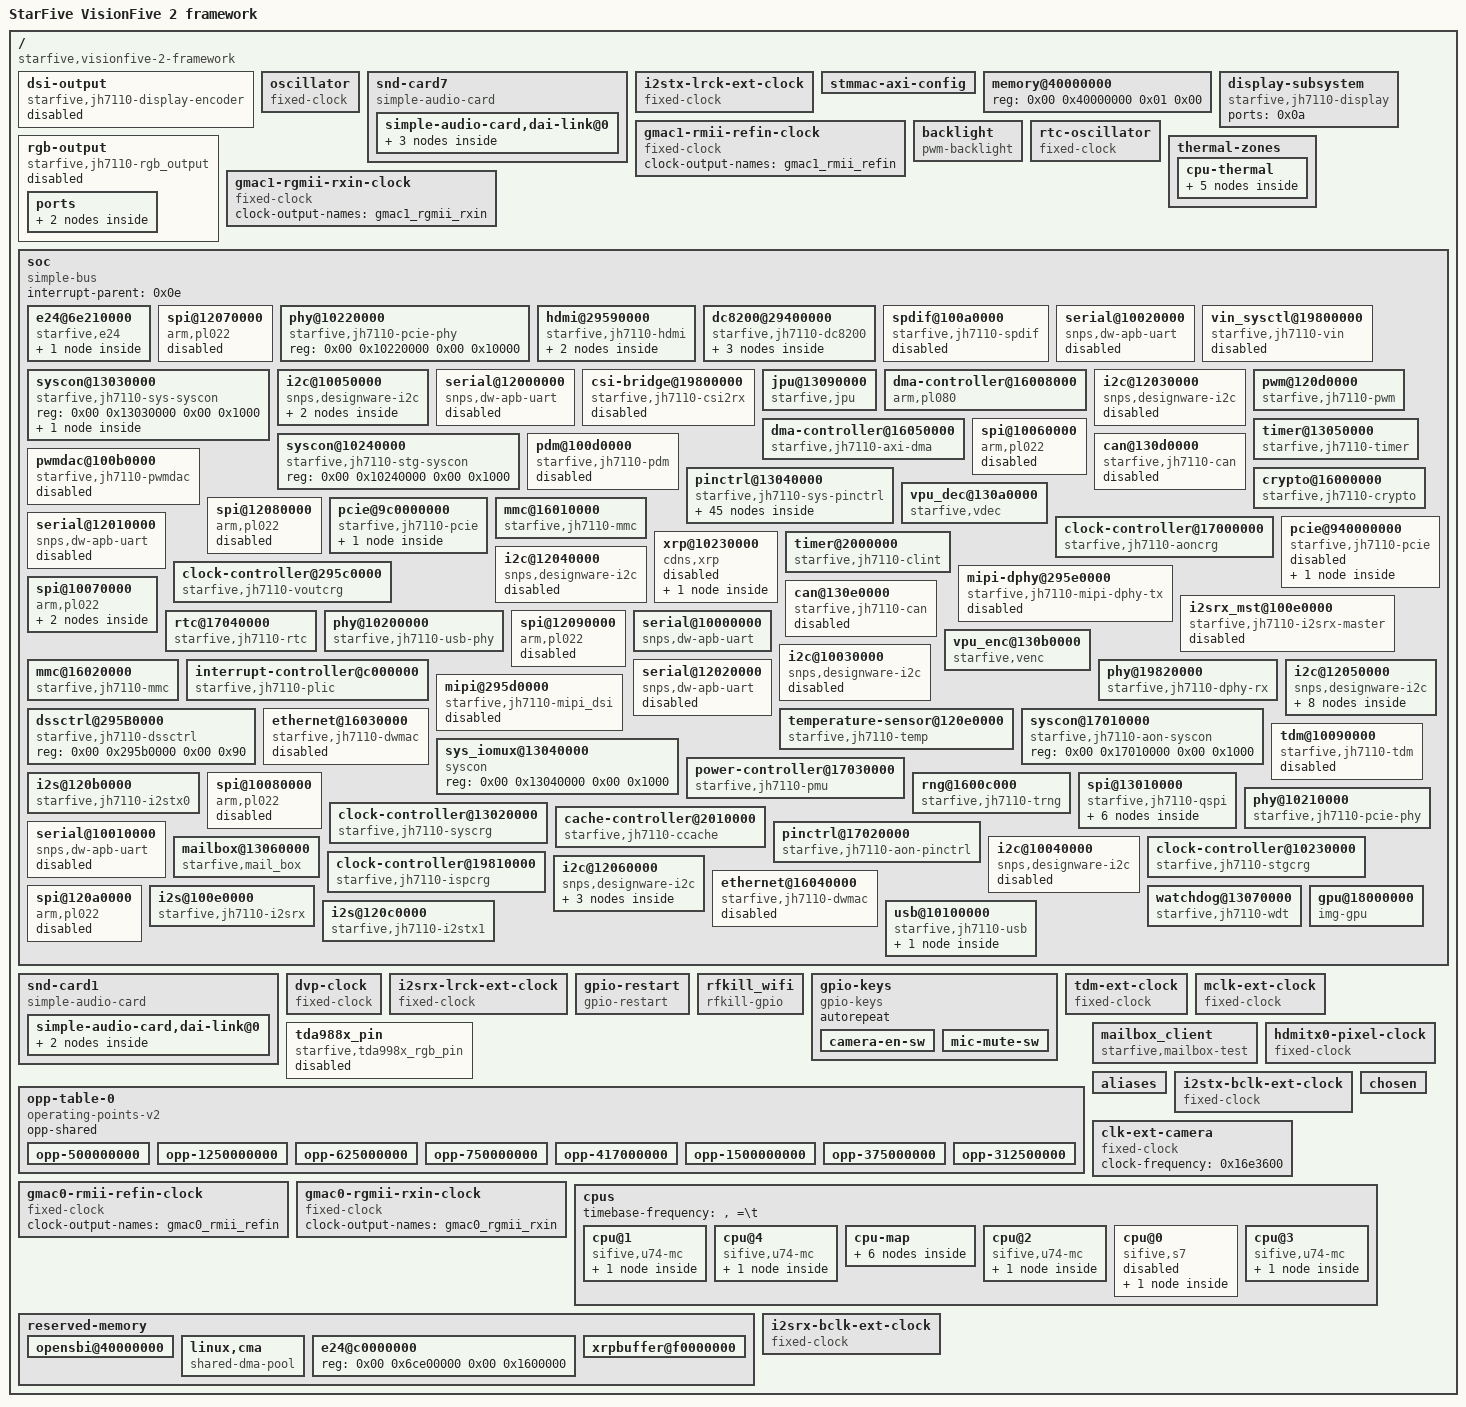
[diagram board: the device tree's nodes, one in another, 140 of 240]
/dts-v1/;

/ {
	#address-cells = <0x02>;
	model = "StarFive VisionFive 2 framework";
	serial-number = "FML13V01-2451-D008EC00-00000902";
	#size-cells = <0x02>;
	compatible = "starfive,visionfive-2-framework", "starfive,jh7110";

	dsi-output {
		compatible = "starfive,jh7110-display-encoder", "verisilicon,dsi-encoder";
		status = "disabled";
	};

	oscillator {
		clock-output-names = "osc";
		#clock-cells = <0x00>;
		clock-frequency = <0x16e3600>;
		compatible = "fixed-clock";
		phandle = <0x25>;
	};

	snd-card7 {
		simple-audio-card,name = "Starfive-ES8326-Sound-Card";
		#address-cells = <0x01>;
		#size-cells = <0x00>;
		compatible = "simple-audio-card";

		simple-audio-card,dai-link@0 {
			mclk-fs = <0x100>;
			format = "i2s";
			frame-master = <0x4f>;
			status = "okay";
			bitclock-master = <0x4f>;
			reg = <0x00>;

			cpu1 {
				sound-dai = <0x51>;
			};

			codec {
				phandle = <0x4f>;
				sound-dai = <0x52>;
			};

			cpu0 {
				sound-dai = <0x50>;
			};
		};
	};

	i2stx-lrck-ext-clock {
		clock-output-names = "i2stx_lrck_ext";
		#clock-cells = <0x00>;
		clock-frequency = <0x2ee00>;
		compatible = "fixed-clock";
		phandle = <0x2a>;
	};

	stmmac-axi-config {
		snps,lpi_en;
		snps,wr_osr_lmt = <0x0f>;
		phandle = <0x37>;
		snps,blen = <0x100 0x80 0x40 0x20 0x00 0x00 0x00>;
		snps,rd_osr_lmt = <0x0f>;
	};

	memory@40000000 {
		device_type = "memory";
		reg = <0x00 0x40000000 0x01 0x00>;
	};

	gmac1-rmii-refin-clock {
		clock-output-names = "gmac1_rmii_refin";
		#clock-cells = <0x00>;
		compatible = "fixed-clock";
		phandle = <0x2d>;
	};

	display-subsystem {
		ports = <0x0a>;
		compatible = "starfive,jh7110-display", "verisilicon,display-subsystem";
		status = "okay";
	};

	backlight {
		default-brightness-level = <0xff>;
		compatible = "pwm-backlight";
		status = "okay";
		brightness-levels = <0x00 0x01 0x02 0x03 0x04 0x05 0x06 0x07 0x08 0x09 0x0a 0x0b 0x0c 0x0d 0x0e 0x0f 0x10 0x11 0x12 0x13 0x14 0x15 0x16 0x17 0x18 0x19 0x1a 0x1b 0x1c 0x1d 0x1e 0x1f 0x20 0x21 0x22 0x23 0x24 0x25 0x26 0x27 0x28 0x29 0x2a 0x2b 0x2c 0x2d 0x2e 0x2f 0x30 0x31 0x32 0x33 0x34 0x35 0x36 0x37 0x38 0x39 0x3a 0x3b 0x3c 0x3d 0x3e 0x3f 0x40 0x41 0x42 0x43 0x44 0x45 0x46 0x47 0x48 0x49 0x4a 0x4b 0x4c 0x4d 0x4e 0x4f 0x50 0x51 0x52 0x53 0x54 0x55 0x56 0x57 0x58 0x59 0x5a 0x5b 0x5c 0x5d 0x5e 0x5f 0x60 0x61 0x62 0x63 0x64 0x65 0x66 0x67 0x68 0x69 0x6a 0x6b 0x6c 0x6d 0x6e 0x6f 0x70 0x71 0x72 0x73 0x74 0x75 0x76 0x77 0x78 0x79 0x7a 0x7b 0x7c 0x7d 0x7e 0x7f 0x80 0x81 0x82 0x83 0x84 0x85 0x86 0x87 0x88 0x89 0x8a 0x8b 0x8c 0x8d 0x8e 0x8f 0x90 0x91 0x92 0x93 0x94 0x95 0x96 0x97 0x98 0x99 0x9a 0x9b 0x9c 0x9d 0x9e 0x9f 0xa0 0xa1 0xa2 0xa3 0xa4 0xa5 0xa6 0xa7 0xa8 0xa9 0xaa 0xab 0xac 0xad 0xae 0xaf 0xb0 0xb1 0xb2 0xb3 0xb4 0xb5 0xb6 0xb7 0xb8 0xb9 0xba 0xbb 0xbc 0xbd 0xbe 0xbf 0xc0 0xc1 0xc2 0xc3 0xc4 0xc5 0xc6 0xc7 0xc8 0xc9 0xca 0xcb 0xcc 0xcd 0xce 0xcf 0xd0 0xd1 0xd2 0xd3 0xd4 0xd5 0xd6 0xd7 0xd8 0xd9 0xda 0xdb 0xdc 0xdd 0xde 0xdf 0xe0 0xe1 0xe2 0xe3 0xe4 0xe5 0xe6 0xe7 0xe8 0xe9 0xea 0xeb 0xec 0xed 0xee 0xef 0xf0 0xf1 0xf2 0xf3 0xf4 0xf5 0xf6 0xf7 0xf8 0xf9 0xfa 0xfb 0xfc 0xfd 0xfe 0xff>;
		pwms = <0x4e 0x00 0x4c4b40 0x00>;
	};

	rgb-output {
		compatible = "starfive,jh7110-rgb_output", "verisilicon,rgb-encoder";
		status = "disabled";

		ports {
			#address-cells = <0x01>;
			#size-cells = <0x00>;

			port@0 {
				#address-cells = <0x01>;
				#size-cells = <0x00>;
				reg = <0x00>;

				endpoint@0 {
					remote-endpoint = <0x0a>;
					reg = <0x00>;
					phandle = <0x42>;
				};
			};
		};
	};

	rtc-oscillator {
		clock-output-names = "rtc_osc";
		#clock-cells = <0x00>;
		clock-frequency = <0x8000>;
		compatible = "fixed-clock";
		phandle = <0x3b>;
	};

	thermal-zones {

		cpu-thermal {
			polling-delay = <0x3a98>;
			polling-delay-passive = <0xfa>;
			thermal-sensors = <0x0c>;

			trips {

				cpu_crit {
					temperature = <0x186a0>;
					hysteresis = <0x7d0>;
					type = "critical";
				};

				cpu_alert0 {
					temperature = <0x14c08>;
					hysteresis = <0x7d0>;
					type = "passive";
					phandle = <0x0d>;
				};
			};

			cooling-maps {

				map0 {
					trip = <0x0d>;
					cooling-device = <0x06 0xffffffff 0xffffffff 0x07 0xffffffff 0xffffffff 0x08 0xffffffff 0xffffffff 0x09 0xffffffff 0xffffffff>;
				};
			};
		};
	};

	gmac1-rgmii-rxin-clock {
		clock-output-names = "gmac1_rgmii_rxin";
		#clock-cells = <0x00>;
		compatible = "fixed-clock";
		phandle = <0x2e>;
	};

	soc {
		#address-cells = <0x02>;
		#size-cells = <0x02>;
		interrupt-parent = <0x0e>;
		compatible = "simple-bus";
		ranges;

		e24@6e210000 {
			#address-cells = <0x01>;
			dma-coherent;
			clock-names = "clk_rtc", "clk_core", "clk_dbg";
			reg-names = "ecmd", "espace";
			irq-mode = <0x01>;
			firmware-name = "e24_elf";
			starfive,stg-syscon = <0x20>;
			resets = <0x22 0x04>;
			memory-region = <0x49>;
			clocks = <0x22 0x18 0x22 0x19 0x22 0x1a>;
			#size-cells = <0x01>;
			interrupt-parent = <0x0e>;
			compatible = "starfive,e24";
			ranges = <0x6ce00000 0x00 0x6ce00000 0x1600000>;
			status = "okay";
			reg = <0x00 0x6e210000 0x00 0x1000 0x00 0x6e211000 0x00 0x3f000>;
			mboxes = <0x0b 0x00 0x02 0x0b 0x02 0x00>;
			reset-names = "e24_core";
			mbox-names = "tx", "rx";

			dsp@0 {
			};
		};

		spi@12070000 {
			arm,primecell-periphid = <0x41022>;
			#address-cells = <0x01>;
			num-cs = <0x01>;
			clock-names = "sspclk", "apb_pclk";
			resets = <0x03 0x48>;
			interrupts = <0x34>;
			clocks = <0x03 0x86 0x03 0x86>;
			#size-cells = <0x00>;
			compatible = "arm,pl022", "arm,primecell";
			status = "disabled";
			reg = <0x00 0x12070000 0x00 0x10000>;
		};

		phy@10220000 {
			#phy-cells = <0x00>;
			compatible = "starfive,jh7110-pcie-phy";
			reg = <0x00 0x10220000 0x00 0x10000>;
			phandle = <0x4c>;
		};

		hdmi@29590000 {
			pinctrl-names = "default";
			hdmi_0p9-supply = <0x45>;
			pinctrl-0 = <0x44>;
			clock-names = "sysclk", "mclk", "bclk", "pclk";
			hdmi_1p8-supply = <0x46>;
			resets = <0x40 0x09>;
			interrupts = <0x63>;
			clocks = <0x40 0x11 0x40 0x0f 0x40 0x10 0x41>;
			hpd-gpio = <0x16 0x0f 0x00>;
			#sound-dai-cells = <0x00>;
			compatible = "starfive,jh7110-hdmi", "inno,hdmi";
			status = "okay";
			reg = <0x00 0x29590000 0x00 0x4000>;
			phandle = <0x55>;
			reset-names = "hdmi_tx";

			port {
				#address-cells = <0x01>;
				#size-cells = <0x00>;

				endpoint@0 {
					remote-endpoint = <0x47>;
					reg = <0x00>;
					phandle = <0x43>;
				};
			};
		};

		dc8200@29400000 {
			verisilicon,dss-syscon = <0x3f>;
			clock-names = "noc_disp", "vout_src", "top_vout_axi", "top_vout_ahb", "pix_clk", "vout_pix1", "axi_clk", "core_clk", "vout_ahb", "vout_top_axi", "vout_top_lcd", "hdmitx0_pixelclk", "dc8200_pix0";
			resets = <0x03 0x2b 0x40 0x00 0x40 0x01 0x40 0x02 0x03 0x1a>;
			interrupts = <0x5f>;
			clocks = <0x03 0x3c 0x03 0x3a 0x03 0x3e 0x03 0x3d 0x40 0x07 0x40 0x08 0x40 0x04 0x40 0x05 0x40 0x06 0x03 0x3e 0x40 0x09 0x41 0x40 0x01>;
			compatible = "starfive,jh7110-dc8200", "verisilicon,dc8200";
			status = "okay";
			reg = <0x00 0x29400000 0x00 0x100 0x00 0x29400800 0x00 0x2000 0x00 0x17030000 0x00 0x1000>;
			reset-names = "rst_vout_src", "rst_axi", "rst_ahb", "rst_core", "rst_noc_disp";

			port {
				#address-cells = <0x01>;
				#size-cells = <0x00>;

				endpoint@1 {
					remote-endpoint = <0x43>;
					reg = <0x01>;
					phandle = <0x47>;
				};

				endpoint@0 {
					remote-endpoint = <0x42>;
					reg = <0x00>;
					phandle = <0x0a>;
				};
			};
		};

		spdif@100a0000 {
			clock-names = "apb", "core", "audroot", "mclk_inner", "mclk_ext", "mclk";
			resets = <0x03 0x5f>;
			interrupts = <0x54>;
			clocks = <0x03 0x9f 0x03 0xa0 0x03 0x10 0x03 0x11 0x1b 0x03 0x12>;
			#sound-dai-cells = <0x00>;
			compatible = "starfive,jh7110-spdif";
			status = "disabled";
			interrupt-names = "tx";
			reg = <0x00 0x100a0000 0x00 0x1000>;
			reset-names = "apb";
		};

		serial@10020000 {
			reg-io-width = <0x04>;
			clock-names = "baudclk", "apb_pclk";
			resets = <0x03 0x57 0x03 0x58>;
			interrupts = <0x22>;
			clocks = <0x03 0x96 0x03 0x95>;
			compatible = "snps,dw-apb-uart";
			status = "disabled";
			reg = <0x00 0x10020000 0x00 0x10000>;
			reg-shift = <0x02>;
		};

		vin_sysctl@19800000 {
			power-domains = <0x30 0x05>;
			clock-names = "clk_apb_func", "clk_pclk", "clk_sys_clk", "clk_wrapper_clk_c", "clk_dvp_inv", "clk_axiwr", "clk_mipi_rx0_pxl", "clk_pixel_clk_if0", "clk_pixel_clk_if1", "clk_pixel_clk_if2", "clk_pixel_clk_if3", "clk_m31dphy_cfgclk_in", "clk_m31dphy_refclk_in", "clk_m31dphy_txclkesc_lan0", "clk_ispcore_2x", "clk_isp_axi";
			reg-names = "csi2rx", "vclk", "vrst", "sctrl", "isp", "trst", "pmu", "syscrg";
			resets = <0x3c 0x00 0x3c 0x01 0x3c 0x04 0x3c 0x09 0x3c 0x0a 0x3c 0x0b 0x3c 0x05 0x3c 0x06 0x3c 0x07 0x3c 0x08 0x3c 0x02 0x3c 0x03 0x03 0x29 0x03 0x2a>;
			interrupts = <0x5c 0x57 0x58 0x59 0x5a>;
			clocks = <0x3c 0x00 0x3c 0x06 0x3c 0x07 0x3c 0x0d 0x3c 0x02 0x3c 0x0c 0x3c 0x01 0x3c 0x08 0x3c 0x09 0x3c 0x0a 0x3c 0x0b 0x3c 0x03 0x3c 0x04 0x3c 0x05 0x03 0x33 0x03 0x34>;
			starfive,aon-syscon = <0x38 0x00>;
			compatible = "starfive,jh7110-vin";
			status = "disabled";
			reg = <0x00 0x19800000 0x00 0x10000 0x00 0x19810000 0x00 0x10000 0x00 0x19820000 0x00 0x10000 0x00 0x19840000 0x00 0x10000 0x00 0x19870000 0x00 0x30000 0x00 0x11840000 0x00 0x10000 0x00 0x17030000 0x00 0x10000 0x00 0x13020000 0x00 0x10000>;
			reset-names = "rst_wrapper_p", "rst_wrapper_c", "rst_pclk", "rst_sys_clk", "rst_axird", "rst_axiwr", "rst_pixel_clk_if0", "rst_pixel_clk_if1", "rst_pixel_clk_if2", "rst_pixel_clk_if3", "rst_m31dphy_hw", "rst_m31dphy_b09_always_on", "rst_isp_top_n", "rst_isp_top_axi";
		};

		syscon@13030000 {
			compatible = "starfive,jh7110-sys-syscon", "syscon", "simple-mfd";
			reg = <0x00 0x13030000 0x00 0x1000>;
			phandle = <0x1c>;

			clock-controller {
				clocks = <0x25>;
				#clock-cells = <0x01>;
				compatible = "starfive,jh7110-pll";
				phandle = <0x2f>;
			};
		};

		i2c@10050000 {
			pinctrl-names = "default";
			#address-cells = <0x01>;
			i2c-sda-hold-time-ns = <0x12c>;
			pinctrl-0 = <0x15>;
			clock-names = "ref";
			i2c-scl-falling-time-ns = <0x1fe>;
			i2c-sda-falling-time-ns = <0x1fe>;
			resets = <0x03 0x4e>;
			interrupts = <0x25>;
			clocks = <0x03 0x8c>;
			#size-cells = <0x00>;
			clock-frequency = <0x186a0>;
			compatible = "snps,designware-i2c";
			status = "okay";
			reg = <0x00 0x10050000 0x00 0x10000>;

			es8326@19 {
				spk-ctl-gpio = <0x16 0x31 0x00>;
				everest,mic2-src = [44];
				everest,jack-pol = [0e];
				irq-gpio = <0x16 0x2e 0x00>;
				#sound-dai-cells = <0x00>;
				everest,interrupt-src = [08];
				compatible = "everest,es8326";
				status = "okay";
				reg = <0x19>;
				phandle = <0x52>;
				everest,mic1-src = [00];
				everest,interrupt-clk = [45];
			};

			touchscreen@14 {
				irq-gpios = <0x16 0x1e 0x00>;
				reset-gpios = <0x16 0x1f 0x00>;
				compatible = "goodix,gt911";
				status = "disabled";
				reg = <0x14>;
			};
		};

		serial@12000000 {
			reg-io-width = <0x04>;
			clock-names = "baudclk", "apb_pclk";
			resets = <0x03 0x59 0x03 0x5a>;
			interrupts = <0x2d>;
			clocks = <0x03 0x98 0x03 0x97>;
			compatible = "snps,dw-apb-uart";
			status = "disabled";
			reg = <0x00 0x12000000 0x00 0x10000>;
			reg-shift = <0x02>;
		};

		csi-bridge@19800000 {
			phy-names = "dphy";
			clock-names = "sys_clk", "p_clk", "pixel_if0_clk", "pixel_if1_clk", "pixel_if2_clk", "pixel_if3_clk";
			resets = <0x3c 0x09 0x3c 0x04 0x3c 0x05 0x3c 0x06 0x3c 0x07 0x3c 0x08>;
			clocks = <0x3c 0x07 0x3c 0x06 0x3c 0x08 0x3c 0x09 0x3c 0x0a 0x3c 0x0b>;
			compatible = "starfive,jh7110-csi2rx";
			status = "disabled";
			phys = <0x3d>;
			reg = <0x00 0x19800000 0x00 0x10000>;
			reset-names = "sys", "reg_bank", "pixel_if0", "pixel_if1", "pixel_if2", "pixel_if3";
		};

		jpu@13090000 {
			power-domains = <0x30 0x03>;
			dma-coherent;
			clock-names = "axi_clk", "core_clk", "apb_clk", "noc_bus", "main_clk", "dec_clk";
			resets = <0x03 0x2c 0x03 0x2d 0x03 0x2e>;
			interrupts = <0x0e>;
			clocks = <0x03 0x42 0x03 0x43 0x03 0x44 0x03 0x4c 0x03 0x4b 0x03 0x4a>;
			compatible = "starfive,jpu";
			status = "okay";
			reg = <0x00 0x13090000 0x00 0x300>;
			reset-names = "rst_axi", "rst_core", "rst_apb";
		};

		dma-controller@16008000 {
			memcpy-bus-width = <0x20>;
			arm,primecell-periphid = <0x41080>;
			lli-bus-interface-ahb1;
			clock-names = "apb_pclk";
			resets = <0x22 0x03>;
			interrupts = <0x1d>;
			clocks = <0x22 0x0f>;
			memcpy-burst-size = <0x100>;
			compatible = "arm,pl080", "arm,primecell";
			mem-bus-interface-ahb1;
			reg = <0x00 0x16008000 0x00 0x4000>;
			phandle = <0x31>;
			#dma-cells = <0x02>;
		};

		i2c@12030000 {
			#address-cells = <0x01>;
			clock-names = "ref";
			resets = <0x03 0x4f>;
			interrupts = <0x30>;
			clocks = <0x03 0x8d>;
			#size-cells = <0x00>;
			compatible = "snps,designware-i2c";
			status = "disabled";
			reg = <0x00 0x12030000 0x00 0x10000>;
		};

		dma-controller@16050000 {
			snps,data-width = <0x03>;
			snps,priority = <0x00 0x01 0x02 0x03>;
			clock-names = "core-clk", "cfgr-clk";
			resets = <0x22 0x05 0x22 0x06>;
			interrupts = <0x49>;
			clocks = <0x22 0x1b 0x22 0x1c>;
			snps,axi-max-burst-len = <0x10>;
			snps,dma-masters = <0x01>;
			compatible = "starfive,jh7110-axi-dma";
			snps,block-size = <0x10000 0x10000 0x10000 0x10000>;
			reg = <0x00 0x16050000 0x00 0x10000>;
			phandle = <0x19>;
			dma-channels = <0x04>;
			#dma-cells = <0x01>;
		};

		pwm@120d0000 {
			pinctrl-names = "default";
			pinctrl-0 = <0x2c>;
			resets = <0x03 0x6c>;
			clocks = <0x03 0x79>;
			#pwm-cells = <0x03>;
			compatible = "starfive,jh7110-pwm", "opencores,pwm-v1";
			status = "okay";
			reg = <0x00 0x120d0000 0x00 0x10000>;
			phandle = <0x4e>;
		};

		syscon@10240000 {
			compatible = "starfive,jh7110-stg-syscon", "syscon";
			reg = <0x00 0x10240000 0x00 0x1000>;
			phandle = <0x20>;
		};

		timer@13050000 {
			clock-names = "apb", "ch0", "ch1", "ch2", "ch3";
			resets = <0x03 0x75 0x03 0x76 0x03 0x77 0x03 0x78 0x03 0x79>;
			interrupts = <0x45 0x46 0x47 0x48>;
			clocks = <0x03 0x7c 0x03 0x7d 0x03 0x7e 0x03 0x7f 0x03 0x80>;
			compatible = "starfive,jh7110-timer";
			reg = <0x00 0x13050000 0x00 0x10000>;
			reset-names = "apb", "ch0", "ch1", "ch2", "ch3";
		};

		spi@10060000 {
			arm,primecell-periphid = <0x41022>;
			#address-cells = <0x01>;
			num-cs = <0x01>;
			clock-names = "sspclk", "apb_pclk";
			resets = <0x03 0x45>;
			interrupts = <0x26>;
			clocks = <0x03 0x83 0x03 0x83>;
			#size-cells = <0x00>;
			compatible = "arm,pl022", "arm,primecell";
			status = "disabled";
			reg = <0x00 0x10060000 0x00 0x10000>;
		};

		pdm@100d0000 {
			clock-names = "pdm_mclk", "pdm_apb", "clk_mclk", "mclk_ext";
			reg-names = "pdm";
			resets = <0x03 0x61 0x03 0x62>;
			clocks = <0x03 0xb6 0x03 0xb7 0x03 0x12 0x1b>;
			#sound-dai-cells = <0x00>;
			compatible = "starfive,jh7110-pdm";
			status = "disabled";
			reg = <0x00 0x100d0000 0x00 0x1000>;
			reset-names = "pdm_dmic", "pdm_apb";
		};

		pwmdac@100b0000 {
			clock-names = "apb", "core";
			resets = <0x03 0x60>;
			clocks = <0x03 0x9d 0x03 0x9e>;
			dma-names = "tx";
			#sound-dai-cells = <0x00>;
			compatible = "starfive,jh7110-pwmdac";
			status = "disabled";
			reg = <0x00 0x100b0000 0x00 0x1000>;
			dmas = <0x19 0x16>;
		};

		can@130d0000 {
			syscon,can_or_canfd = <0x00>;
			clock-names = "apb_clk", "core_clk", "timer_clk";
			starfive,sys-syscon = <0x1c 0x10 0x03 0x08>;
			resets = <0x03 0x6f 0x03 0x70 0x03 0x71>;
			interrupts = <0x70>;
			clocks = <0x03 0x73 0x03 0x75 0x03 0x74>;
			compatible = "starfive,jh7110-can", "ipms,can";
			status = "disabled";
			frequency = <0x2625a00>;
			reg = <0x00 0x130d0000 0x00 0x1000>;
			reset-names = "rst_apb", "rst_core", "rst_timer";
		};

		pinctrl@13040000 {
			gpio-controller;
			resets = <0x03 0x02>;
			interrupts = <0x56>;
			clocks = <0x03 0x70>;
			compatible = "starfive,jh7110-sys-pinctrl";
			#interrupt-cells = <0x02>;
			reg = <0x00 0x13040000 0x00 0x10000>;
			phandle = <0x16>;
			#gpio-cells = <0x02>;
			interrupt-controller;

			mmc1-0 {
				phandle = <0x35>;

				clk-pins {
					input-schmitt-disable;
					input-disable;
					drive-strength = <0x0c>;
					pinmux = <0xff37000a>;
					slew-rate = <0x00>;
					bias-pull-up;
				};

				mmc-pins {
					drive-strength = <0x0c>;
					pinmux = <0x2c394c09 0x2d3a500b 0x2e3b540c 0x2f3c5807 0x303d5c08>;
					input-schmitt-enable;
					slew-rate = <0x00>;
					bias-pull-up;
					input-enable;
				};
			};

			i2c2-0 {
				phandle = <0x15>;

				i2c-pins {
					bias-disable;
					pinmux = <0x3b007803 0x3c007c02>;
					input-schmitt-enable;
					input-enable;
				};
			};

			i2c5-0 {
				phandle = <0x26>;

				i2c-pins {
					bias-disable;
					pinmux = <0x4f00a813 0x5000ac14>;
					input-schmitt-enable;
					input-enable;
				};
			};

			mmc0-0 {
				phandle = <0x32>;

				mmc-pins {
					drive-strength = <0x0c>;
					pinmux = <0x440 0x441 0x442 0x443 0x444 0x445 0x446 0x447 0x448 0x449>;
					bias-pull-up;
					input-enable;
				};

				rst-pins {
					input-schmitt-disable;
					input-disable;
					drive-strength = <0x0c>;
					pinmux = <0xff13003e>;
					slew-rate = <0x00>;
					bias-pull-up;
				};
			};

			i2srx-0 {
				phandle = <0x1f>;

				clk-sd-pins {
					pinmux = <0x1f000426 0x2000043f 0x21000426 0x2200043f 0x1700042c>;
					input-enable;
				};
			};

			hdmi-0 {
				phandle = <0x44>;

				cec-pins {
					pinmux = <0x50a080e>;
					bias-pull-up;
					input-enable;
				};

				hpd-pins {
					bias-disable;
					pinmux = <0x800040f>;
					input-enable;
				};

				scl-pins {
					pinmux = <0x60b0c00>;
					bias-pull-up;
					input-enable;
				};

				sda-pins {
					pinmux = <0x70c1001>;
					bias-pull-up;
					input-enable;
				};
			};

			pwmdac-0 {

				pwmdac-pins {
					input-schmitt-disable;
					input-disable;
					drive-strength = <0x02>;
					bias-disable;
					pinmux = <0xff1c0021 0xff1d0022>;
					slew-rate = <0x00>;
				};
			};

			uart0-0 {
				phandle = <0x14>;

				tx-pins {
					input-schmitt-disable;
					input-disable;
					drive-strength = <0x0c>;
					bias-disable;
					pinmux = <0xff140005>;
					slew-rate = <0x00>;
				};

				rx-pins {
					drive-strength = <0x02>;
					bias-disable;
					pinmux = <0xe000406>;
					input-schmitt-enable;
					slew-rate = <0x00>;
					input-enable;
				};
			};

			pcie1-0 {
				phandle = <0x4d>;

				clkreq-pins {
					input-schmitt-disable;
					drive-strength = <0x02>;
					pinmux = <0xff00041d>;
					bias-pull-down;
					slew-rate = <0x00>;
					input-enable;
				};

				wake-pins {
					input-schmitt-disable;
					drive-strength = <0x02>;
					pinmux = <0xff01041c>;
					slew-rate = <0x00>;
					bias-pull-up;
					input-enable;
				};
			};

			tdm-0 {
				phandle = <0x1a>;

				pcmclk-pins {
					pinmux = <0x23010426>;
					input-enable;
				};

				sync-pins {
					pinmux = <0x2501043f>;
					input-enable;
				};

				tx-pins {
					input-schmitt-disable;
					input-disable;
					drive-strength = <0x02>;
					pinmux = <0xff29002c>;
					slew-rate = <0x00>;
					bias-pull-up;
				};

				rx-pins {
					pinmux = <0x2401043d>;
					input-enable;
				};
			};

			i2stx1-0 {
				phandle = <0x2b>;

				sd-pins {
					input-disable;
					bias-disable;
					pinmux = <0xff45003d>;
				};
			};

			i2c6-0 {
				phandle = <0x27>;

				i2c-pins {
					bias-disable;
					pinmux = <0x5600b810 0x5700bc11>;
					input-schmitt-enable;
					input-enable;
				};
			};

			pwm-0 {
				phandle = <0x2c>;

				pwm-pins {
					input-schmitt-disable;
					input-disable;
					drive-strength = <0x0c>;
					bias-disable;
					pinmux = <0xff182416>;
					slew-rate = <0x00>;
				};
			};

			pcie0-0 {

				clkreq-pins {
					input-schmitt-disable;
					drive-strength = <0x02>;
					pinmux = <0xff00041b>;
					bias-pull-down;
					slew-rate = <0x00>;
					input-enable;
				};

				wake-pins {
					input-schmitt-disable;
					drive-strength = <0x02>;
					pinmux = <0xff000420>;
					slew-rate = <0x00>;
					bias-pull-up;
					input-enable;
				};
			};

			mclk-ext-0 {
				phandle = <0x28>;

				mclk-ext-pins {
					pinmux = <0x1e000404>;
					input-enable;
				};
			};

			spi1-0 {
				phandle = <0x17>;

				miso-pins {
					pinmux = <0x3a000424>;
					input-schmitt-enable;
					bias-pull-up;
					input-enable;
				};

				mosi-pins {
					input-schmitt-disable;
					input-disable;
					bias-disable;
					pinmux = <0xff4b0027>;
				};

				sck-pins {
					input-schmitt-disable;
					input-disable;
					bias-disable;
					pinmux = <0x3849003a>;
				};
			};
		};

		crypto@16000000 {
			clock-names = "hclk", "ahb";
			resets = <0x22 0x03>;
			interrupts = <0x1c>;
			clocks = <0x22 0x0f 0x22 0x10>;
			dma-names = "tx", "rx";
			compatible = "starfive,jh7110-crypto";
			reg = <0x00 0x16000000 0x00 0x4000>;
			dmas = <0x31 0x01 0x02 0x31 0x00 0x02>;
		};

		vpu_dec@130a0000 {
			power-domains = <0x30 0x03>;
			dma-coherent;
			clock-names = "axi_clk", "bpu_clk", "vce_clk", "apb_clk", "noc_bus", "main_clk";
			resets = <0x03 0x2f 0x03 0x30 0x03 0x31 0x03 0x32 0x03 0x35>;
			interrupts = <0x0d>;
			clocks = <0x03 0x46 0x03 0x47 0x03 0x48 0x03 0x49 0x03 0x4c 0x03 0x4b>;
			compatible = "starfive,vdec";
			status = "okay";
			reg = <0x00 0x130a0000 0x00 0x10000>;
			starfive,vdec_noc_ctrl;
			reset-names = "rst_axi", "rst_bpu", "rst_vce", "rst_apb", "rst_sram";
		};

		spi@12080000 {
			arm,primecell-periphid = <0x41022>;
			#address-cells = <0x01>;
			num-cs = <0x01>;
			clock-names = "sspclk", "apb_pclk";
			resets = <0x03 0x49>;
			interrupts = <0x35>;
			clocks = <0x03 0x87 0x03 0x87>;
			#size-cells = <0x00>;
			compatible = "arm,pl022", "arm,primecell";
			status = "disabled";
			reg = <0x00 0x12080000 0x00 0x10000>;
		};

		pcie@9c0000000 {
			pinctrl-names = "default";
			#address-cells = <0x03>;
			bus-range = <0x00 0xff>;
			pinctrl-0 = <0x4d>;
			clock-names = "noc", "tl", "axi_mst0", "apb";
			reg-names = "cfg", "apb";
			starfive,stg-syscon = <0x20>;
			resets = <0x22 0x11 0x22 0x12 0x22 0x13 0x22 0x14 0x22 0x15 0x22 0x16>;
			interrupts = <0x39>;
			clocks = <0x03 0x60 0x22 0x0d 0x22 0x0b 0x22 0x0c>;
			interrupt-map = <0x00 0x00 0x00 0x01 0x4b 0x01 0x00 0x00 0x00 0x02 0x4b 0x02 0x00 0x00 0x00 0x03 0x4b 0x03 0x00 0x00 0x00 0x04 0x4b 0x04>;
			#size-cells = <0x02>;
			perst-gpios = <0x16 0x15 0x01>;
			msi-controller;
			device_type = "pci";
			interrupt-map-mask = <0x00 0x00 0x00 0x07>;
			compatible = "starfive,jh7110-pcie";
			ranges = <0x82000000 0x00 0x38000000 0x00 0x38000000 0x00 0x8000000 0xc3000000 0x09 0x80000000 0x09 0x80000000 0x00 0x40000000>;
			#interrupt-cells = <0x01>;
			status = "okay";
			phys = <0x4c>;
			reg = <0x09 0xc0000000 0x00 0x1000000 0x00 0x2c000000 0x00 0x100000>;
			linux,pci-domain = <0x01>;
			reset-names = "mst0", "slv0", "slv", "brg", "core", "apb";

			interrupt-controller {
				#address-cells = <0x00>;
				#interrupt-cells = <0x01>;
				phandle = <0x4b>;
				interrupt-controller;
			};
		};

		mmc@16010000 {
			fifo-depth = <0x20>;
			pinctrl-names = "default";
			data-addr = <0x00>;
			pinctrl-0 = <0x32>;
			clock-names = "biu", "ciu";
			vqmmc-supply = <0x34>;
			assigned-clocks = <0x03 0x5d>;
			mmc-hs200-1_8v;
			bus-width = <0x08>;
			non-removable;
			assigned-clock-rates = <0x2faf080>;
			resets = <0x03 0x40>;
			interrupts = <0x4a>;
			clocks = <0x03 0x5b 0x03 0x5d>;
			vmmc-supply = <0x33>;
			cap-mmc-hw-reset;
			mmc-ddr-1_8v;
			compatible = "starfive,jh7110-mmc";
			post-power-on-delay-ms = <0xc8>;
			status = "okay";
			fifo-watermark-aligned;
			reg = <0x00 0x16010000 0x00 0x10000>;
			max-frequency = <0x5f5e100>;
			cap-mmc-highspeed;
			reset-names = "reset";
			starfive,sysreg = <0x1c 0x14 0x1a 0x7c000000>;
		};

		clock-controller@17000000 {
			#reset-cells = <0x01>;
			clock-names = "osc", "gmac0_rmii_refin", "gmac0_rgmii_rxin", "stg_axiahb", "apb_bus", "gmac0_gtxclk", "rtc_osc";
			clocks = <0x25 0x39 0x3a 0x03 0x08 0x03 0x0b 0x03 0x6c 0x3b>;
			#clock-cells = <0x01>;
			compatible = "starfive,jh7110-aoncrg";
			reg = <0x00 0x17000000 0x00 0x10000>;
			phandle = <0x36>;
		};

		serial@12010000 {
			reg-io-width = <0x04>;
			clock-names = "baudclk", "apb_pclk";
			resets = <0x03 0x5b 0x03 0x5c>;
			interrupts = <0x2e>;
			clocks = <0x03 0x9a 0x03 0x99>;
			compatible = "snps,dw-apb-uart";
			status = "disabled";
			reg = <0x00 0x12010000 0x00 0x10000>;
			reg-shift = <0x02>;
		};

		pcie@940000000 {
			#address-cells = <0x03>;
			bus-range = <0x00 0xff>;
			clock-names = "noc", "tl", "axi_mst0", "apb";
			reg-names = "cfg", "apb";
			starfive,stg-syscon = <0x20>;
			resets = <0x22 0x0b 0x22 0x0c 0x22 0x0d 0x22 0x0e 0x22 0x0f 0x22 0x10>;
			interrupts = <0x38>;
			clocks = <0x03 0x60 0x22 0x0a 0x22 0x08 0x22 0x09>;
			interrupt-map = <0x00 0x00 0x00 0x01 0x4a 0x01 0x00 0x00 0x00 0x02 0x4a 0x02 0x00 0x00 0x00 0x03 0x4a 0x03 0x00 0x00 0x00 0x04 0x4a 0x04>;
			#size-cells = <0x02>;
			msi-controller;
			device_type = "pci";
			interrupt-map-mask = <0x00 0x00 0x00 0x07>;
			compatible = "starfive,jh7110-pcie";
			ranges = <0x82000000 0x00 0x30000000 0x00 0x30000000 0x00 0x8000000 0xc3000000 0x09 0x00 0x09 0x00 0x00 0x40000000>;
			#interrupt-cells = <0x01>;
			status = "disabled";
			phys = <0x24>;
			reg = <0x09 0x40000000 0x00 0x1000000 0x00 0x2b000000 0x00 0x100000>;
			linux,pci-domain = <0x00>;
			reset-names = "mst0", "slv0", "slv", "brg", "core", "apb";

			interrupt-controller {
				#address-cells = <0x00>;
				#interrupt-cells = <0x01>;
				phandle = <0x4a>;
				interrupt-controller;
			};
		};

		xrp@10230000 {
			#address-cells = <0x01>;
			dma-coherent;
			clock-names = "core_clk";
			firmware-name = "hifi4_elf";
			starfive,stg-syscon = <0x20>;
			resets = <0x22 0x01 0x22 0x02>;
			clocks = <0x22 0x00>;
			#size-cells = <0x01>;
			compatible = "cdns,xrp";
			ranges = <0x40000000 0x00 0x20000000 0x40000 0x69c00000 0x00 0x69c00000 0x3000000>;
			status = "disabled";
			reg = <0x00 0x10230000 0x00 0x10000 0x00 0x10240000 0x00 0x10000>;
			reset-names = "rst_core", "rst_axi";

			dsp@0 {
			};
		};

		timer@2000000 {
			interrupts-extended = <0x0f 0x03 0x0f 0x07 0x10 0x03 0x10 0x07 0x11 0x03 0x11 0x07 0x12 0x03 0x12 0x07 0x13 0x03 0x13 0x07>;
			compatible = "starfive,jh7110-clint", "sifive,clint0";
			reg = <0x00 0x2000000 0x00 0x10000>;
		};

		i2c@12040000 {
			#address-cells = <0x01>;
			clock-names = "ref";
			resets = <0x03 0x50>;
			interrupts = <0x31>;
			clocks = <0x03 0x8e>;
			#size-cells = <0x00>;
			compatible = "snps,designware-i2c";
			status = "disabled";
			reg = <0x00 0x12040000 0x00 0x10000>;
		};

		clock-controller@295c0000 {
			power-domains = <0x30 0x04>;
			#reset-cells = <0x01>;
			clock-names = "vout_src", "vout_top_ahb", "vout_top_axi", "vout_top_hdmitx0_mclk", "i2stx0_bclk", "hdmitx0_pixelclk";
			resets = <0x03 0x2b>;
			clocks = <0x03 0x3a 0x03 0x3d 0x03 0x3e 0x03 0x3f 0x03 0xa5 0x41>;
			#clock-cells = <0x01>;
			compatible = "starfive,jh7110-voutcrg";
			reg = <0x00 0x295c0000 0x00 0x10000>;
			phandle = <0x40>;
		};

		mipi-dphy@295e0000 {
			clock-names = "dphy_txesc";
			resets = <0x40 0x0a 0x40 0x0b>;
			clocks = <0x40 0x0e>;
			#phy-cells = <0x00>;
			compatible = "starfive,jh7110-mipi-dphy-tx", "m31,mipi-dphy-tx";
			status = "disabled";
			reg = <0x00 0x295e0000 0x00 0x10000>;
			phandle = <0x48>;
			reset-names = "dphy_sys", "dphy_txbytehs";
		};

		spi@10070000 {
			arm,primecell-periphid = <0x41022>;
			pinctrl-names = "default";
			#address-cells = <0x01>;
			num-cs = <0x01>;
			pinctrl-0 = <0x17>;
			clock-names = "sspclk", "apb_pclk";
			resets = <0x03 0x46>;
			interrupts = <0x27>;
			clocks = <0x03 0x84 0x03 0x84>;
			#size-cells = <0x00>;
			compatible = "arm,pl022", "arm,primecell";
			status = "okay";
			reg = <0x00 0x10070000 0x00 0x10000>;
			cs-gpios = <0x16 0x39 0x01>;

			spi@1 {
				pl022,interface = <0x00>;
				irq-gpio = <0x16 0x1a 0x00>;
				google,cros-ec-spi-msg-delay = <0x0a>;
				spi-max-frequency = <0xf4240>;
				pl022,com-mode = <0x01>;
				compatible = "google,cros-ec-spi";
				status = "okay";
				reg = <0x00>;
				google,cros-ec-spi-pre-delay = <0x0a>;

				keyboard-controller {
					compatible = "google,cros-ec-keyb-switches";
					status = "okay";
				};
			};
		};

		i2srx_mst@100e0000 {
			clock-names = "i2sclk", "apb", "mclk", "mclk_inner", "mclk_ext";
			resets = <0x03 0x63 0x03 0x64>;
			clocks = <0x03 0xb0 0x03 0xaf 0x03 0x12 0x03 0x11 0x1b>;
			dma-names = "rx";
			#sound-dai-cells = <0x00>;
			starfive,syscon = <0x1c 0x18 0x02 0x34 0x3fc00 0x24400>;
			compatible = "starfive,jh7110-i2srx-master";
			status = "disabled";
			reg = <0x00 0x100e0000 0x00 0x1000>;
			dmas = <0x19 0x18>;
		};

		can@130e0000 {
			syscon,can_or_canfd = <0x00>;
			clock-names = "apb_clk", "core_clk", "timer_clk";
			starfive,sys-syscon = <0x1c 0x88 0x12 0x40000>;
			resets = <0x03 0x72 0x03 0x73 0x03 0x74>;
			interrupts = <0x71>;
			clocks = <0x03 0x76 0x03 0x78 0x03 0x77>;
			compatible = "starfive,jh7110-can", "ipms,can";
			status = "disabled";
			frequency = <0x2625a00>;
			reg = <0x00 0x130e0000 0x00 0x1000>;
			reset-names = "rst_apb", "rst_core", "rst_timer";
		};

		rtc@17040000 {
			clock-names = "pclk", "cal_clk";
			resets = <0x36 0x07 0x36 0x05 0x36 0x06>;
			interrupts = <0x0a 0x0b 0x0c>;
			clocks = <0x36 0x0a 0x36 0x0d>;
			compatible = "starfive,jh7110-rtc";
			interrupt-names = "rtc_ms_pulse", "rtc_sec_pulse", "rtc";
			reg = <0x00 0x17040000 0x00 0x10000>;
			reset-names = "rst_osc", "rst_apb", "rst_cal";
			rtc,cal-clock-freq = <0xf4240>;
		};

		phy@10200000 {
			clock-names = "125m", "app_125m";
			clocks = <0x03 0x5f 0x22 0x06>;
			#phy-cells = <0x00>;
			compatible = "starfive,jh7110-usb-phy";
			reg = <0x00 0x10200000 0x00 0x10000>;
			phandle = <0x23>;
		};

		spi@12090000 {
			arm,primecell-periphid = <0x41022>;
			#address-cells = <0x01>;
			num-cs = <0x01>;
			clock-names = "sspclk", "apb_pclk";
			resets = <0x03 0x4a>;
			interrupts = <0x36>;
			clocks = <0x03 0x88 0x03 0x88>;
			#size-cells = <0x00>;
			compatible = "arm,pl022", "arm,primecell";
			status = "disabled";
			reg = <0x00 0x12090000 0x00 0x10000>;
		};

		serial@10000000 {
			reg-io-width = <0x04>;
			pinctrl-names = "default";
			pinctrl-0 = <0x14>;
			clock-names = "baudclk", "apb_pclk";
			resets = <0x03 0x53 0x03 0x54>;
			interrupts = <0x20>;
			clocks = <0x03 0x92 0x03 0x91>;
			compatible = "snps,dw-apb-uart";
			status = "okay";
			reg = <0x00 0x10000000 0x00 0x10000>;
			reg-shift = <0x02>;
		};

		vpu_enc@130b0000 {
			power-domains = <0x30 0x06>;
			dma-coherent;
			clock-names = "axi_clk", "bpu_clk", "vce_clk", "apb_clk", "noc_bus";
			resets = <0x03 0x36 0x03 0x37 0x03 0x38 0x03 0x39 0x03 0x3a>;
			interrupts = <0x0f>;
			clocks = <0x03 0x4e 0x03 0x4f 0x03 0x50 0x03 0x51 0x03 0x52>;
			compatible = "starfive,venc";
			status = "okay";
			reg = <0x00 0x130b0000 0x00 0x10000>;
			starfive,venc_noc_ctrl;
			reset-names = "rst_axi", "rst_bpu", "rst_vce", "rst_apb", "rst_sram";
		};

		i2c@10030000 {
			#address-cells = <0x01>;
			clock-names = "ref";
			resets = <0x03 0x4c>;
			interrupts = <0x23>;
			clocks = <0x03 0x8a>;
			#size-cells = <0x00>;
			compatible = "snps,designware-i2c";
			status = "disabled";
			reg = <0x00 0x10030000 0x00 0x10000>;
		};

		mmc@16020000 {
			fifo-depth = <0x20>;
			pinctrl-names = "default";
			data-addr = <0x00>;
			pinctrl-0 = <0x35>;
			clock-names = "biu", "ciu";
			cap-sd-highspeed;
			assigned-clocks = <0x03 0x5e>;
			no-mmc;
			bus-width = <0x04>;
			no-sdio;
			assigned-clock-rates = <0x2faf080>;
			resets = <0x03 0x41>;
			interrupts = <0x4b>;
			clocks = <0x03 0x5c 0x03 0x5e>;
			broken-cd;
			compatible = "starfive,jh7110-mmc";
			post-power-on-delay-ms = <0xc8>;
			status = "okay";
			fifo-watermark-aligned;
			reg = <0x00 0x16020000 0x00 0x10000>;
			max-frequency = <0x5f5e100>;
			reset-names = "reset";
			starfive,sysreg = <0x1c 0x9c 0x01 0x3e>;
		};

		interrupt-controller@c000000 {
			#address-cells = <0x00>;
			interrupts-extended = <0x0f 0x0b 0x10 0x0b 0x10 0x09 0x11 0x0b 0x11 0x09 0x12 0x0b 0x12 0x09 0x13 0x0b 0x13 0x09>;
			compatible = "starfive,jh7110-plic", "sifive,plic-1.0.0";
			#interrupt-cells = <0x01>;
			reg = <0x00 0xc000000 0x00 0x4000000>;
			phandle = <0x0e>;
			riscv,ndev = <0x88>;
			interrupt-controller;
		};

		phy@19820000 {
			power-domains = <0x38 0x01>;
			clock-names = "cfg", "ref", "tx";
			resets = <0x3c 0x02 0x3c 0x03>;
			clocks = <0x3c 0x03 0x3c 0x04 0x3c 0x05>;
			#phy-cells = <0x00>;
			compatible = "starfive,jh7110-dphy-rx";
			reg = <0x00 0x19820000 0x00 0x10000>;
			phandle = <0x3d>;
		};

		serial@12020000 {
			reg-io-width = <0x04>;
			clock-names = "baudclk", "apb_pclk";
			resets = <0x03 0x5d 0x03 0x5e>;
			interrupts = <0x2f>;
			clocks = <0x03 0x9c 0x03 0x9b>;
			compatible = "snps,dw-apb-uart";
			status = "disabled";
			reg = <0x00 0x12020000 0x00 0x10000>;
			reg-shift = <0x02>;
		};

		dssctrl@295B0000 {
			compatible = "starfive,jh7110-dssctrl", "verisilicon,dss-ctrl", "syscon";
			reg = <0x00 0x295b0000 0x00 0x90>;
			phandle = <0x3f>;
		};

		mipi@295d0000 {
			phy-names = "dphy";
			clock-names = "dpi", "apb", "txesc", "sys";
			reg-names = "dsi";
			resets = <0x40 0x03 0x40 0x04 0x40 0x05 0x40 0x06 0x40 0x07 0x40 0x08>;
			interrupts = <0x62>;
			clocks = <0x40 0x0b 0x40 0x0a 0x40 0x0d 0x40 0x0c>;
			compatible = "starfive,jh7110-mipi_dsi", "cdns,dsi";
			status = "disabled";
			phys = <0x48>;
			reg = <0x00 0x295d0000 0x00 0x10000>;
			reset-names = "dsi_dpi", "dsi_apb", "dsi_rxesc", "dsi_sys", "dsi_txbytehs", "dsi_txesc";
		};

		temperature-sensor@120e0000 {
			clock-names = "sense", "bus";
			resets = <0x03 0x7c 0x03 0x7b>;
			clocks = <0x03 0x82 0x03 0x81>;
			#thermal-sensor-cells = <0x00>;
			compatible = "starfive,jh7110-temp";
			reg = <0x00 0x120e0000 0x00 0x10000>;
			phandle = <0x0c>;
			reset-names = "sense", "bus";
		};

		i2c@12050000 {
			pinctrl-names = "default";
			#address-cells = <0x01>;
			i2c-sda-hold-time-ns = <0x12c>;
			pinctrl-0 = <0x26>;
			clock-names = "ref";
			i2c-scl-falling-time-ns = <0x1fe>;
			i2c-sda-falling-time-ns = <0x1fe>;
			resets = <0x03 0x51>;
			interrupts = <0x32>;
			clocks = <0x03 0x8f>;
			#size-cells = <0x00>;
			clock-frequency = <0x186a0>;
			compatible = "snps,designware-i2c";
			status = "okay";
			reg = <0x00 0x12050000 0x00 0x10000>;

			pmic@36 {
				interrupts = <0x00>;
				compatible = "x-powers,axp15060";
				#interrupt-cells = <0x01>;
				reg = <0x36>;
				interrupt-controller;

				regulators {

					ALDO5 {
						regulator-max-microvolt = <0xdbba0>;
						regulator-boot-on;
						regulator-min-microvolt = <0xdbba0>;
						regulator-name = "hdmi_0p9";
						phandle = <0x45>;
						regulator-compatible = "aldo5";
					};

					dcdc1 {
						regulator-max-microvolt = <0x325aa0>;
						regulator-boot-on;
						regulator-always-on;
						regulator-min-microvolt = <0x325aa0>;
						regulator-name = "vcc_3v3";
						phandle = <0x33>;
						regulator-compatible = "dcdc1";
					};

					ALDO3 {
						regulator-max-microvolt = <0x1b7740>;
						regulator-boot-on;
						regulator-min-microvolt = <0x1b7740>;
						regulator-name = "hdmi_1p8";
						phandle = <0x46>;
						regulator-compatible = "aldo3";
					};

					ALDO1 {
						regulator-max-microvolt = <0xdbba0>;
						regulator-boot-on;
						regulator-min-microvolt = <0xdbba0>;
						regulator-name = "mipi_0p9";
						regulator-compatible = "aldo1";
					};

					aldo4 {
						regulator-max-microvolt = <0x1b7740>;
						regulator-boot-on;
						regulator-always-on;
						regulator-min-microvolt = <0x1b7740>;
						regulator-name = "emmc_vdd";
						phandle = <0x34>;
						regulator-compatible = "aldo4";
					};

					dcdc2 {
						regulator-max-microvolt = <0x177fa0>;
						regulator-always-on;
						regulator-min-microvolt = <0x7a120>;
						regulator-name = "vdd-cpu";
						phandle = <0x04>;
						regulator-compatible = "dcdc2";
					};
				};
			};
		};

		ethernet@16030000 {
			snps,multicast-filter-bins = <0x40>;
			snps,txpbl = <0x10>;
			clock-names = "stmmaceth", "pclk", "ptp_ref", "tx", "gtx";
			snps,en-tx-lpi-clockgating;
			snps,fixed-burst;
			resets = <0x36 0x00 0x36 0x01>;
			interrupts = <0x07 0x06 0x05>;
			clocks = <0x36 0x03 0x36 0x02 0x03 0x6d 0x36 0x06 0x03 0x6f>;
			snps,no-pbl-x8;
			snps,tso;
			starfive,syscon = <0x38 0x0c 0x12>;
			snps,rxpbl = <0x10>;
			compatible = "starfive,jh7110-dwmac", "snps,dwmac-5.20";
			status = "disabled";
			tx-fifo-depth = <0x800>;
			interrupt-names = "macirq", "eth_wake_irq", "eth_lpi";
			snps,force_thresh_dma_mode;
			rx-fifo-depth = <0x800>;
			reg = <0x00 0x16030000 0x00 0x10000>;
			reset-names = "stmmaceth", "ahb";
			snps,axi-config = <0x37>;
			snps,perfect-filter-entries = <0x100>;
		};

		syscon@17010000 {
			#power-domain-cells = <0x01>;
			compatible = "starfive,jh7110-aon-syscon", "syscon";
			reg = <0x00 0x17010000 0x00 0x1000>;
			phandle = <0x38>;
		};

		tdm@10090000 {
			pinctrl-names = "default";
			pinctrl-0 = <0x1a>;
			clock-names = "tdm_ahb", "tdm_apb", "tdm_internal", "tdm", "mclk_inner", "tdm_ext";
			resets = <0x03 0x69 0x03 0x6b 0x03 0x6a>;
			clocks = <0x03 0xb8 0x03 0xb9 0x03 0xba 0x03 0xbb 0x03 0x11 0x18>;
			dma-names = "rx", "tx";
			#sound-dai-cells = <0x00>;
			compatible = "starfive,jh7110-tdm";
			status = "disabled";
			reg = <0x00 0x10090000 0x00 0x1000>;
			dmas = <0x19 0x14 0x19 0x15>;
		};

		sys_iomux@13040000 {
			compatible = "syscon";
			reg = <0x00 0x13040000 0x00 0x1000>;
			phandle = <0x21>;
		};

		power-controller@17030000 {
			interrupts = <0x6f>;
			#power-domain-cells = <0x01>;
			compatible = "starfive,jh7110-pmu";
			reg = <0x00 0x17030000 0x00 0x10000>;
			phandle = <0x30>;
		};

		i2s@120b0000 {
			pinctrl-names = "default";
			pinctrl-0 = <0x28>;
			clock-names = "i2sclk", "apb", "mclk", "mclk_inner", "mclk_ext";
			resets = <0x03 0x65 0x03 0x66>;
			clocks = <0x03 0xa2 0x03 0xa1 0x03 0x12 0x03 0x11 0x1b>;
			dma-names = "tx";
			#sound-dai-cells = <0x00>;
			compatible = "starfive,jh7110-i2stx0";
			status = "okay";
			reg = <0x00 0x120b0000 0x00 0x1000>;
			phandle = <0x54>;
			dmas = <0x19 0x2f>;
		};

		spi@10080000 {
			arm,primecell-periphid = <0x41022>;
			#address-cells = <0x01>;
			num-cs = <0x01>;
			clock-names = "sspclk", "apb_pclk";
			resets = <0x03 0x47>;
			interrupts = <0x28>;
			clocks = <0x03 0x85 0x03 0x85>;
			#size-cells = <0x00>;
			compatible = "arm,pl022", "arm,primecell";
			status = "disabled";
			reg = <0x00 0x10080000 0x00 0x10000>;
		};

		rng@1600c000 {
			clock-names = "hclk", "ahb";
			resets = <0x22 0x03>;
			interrupts = <0x1e>;
			clocks = <0x22 0x0f 0x22 0x10>;
			compatible = "starfive,jh7110-trng";
			reg = <0x00 0x1600c000 0x00 0x4000>;
		};

		spi@13010000 {
			#address-cells = <0x01>;
			clock-names = "ref", "ahb", "apb";
			resets = <0x03 0x3e 0x03 0x3d 0x03 0x3f>;
			interrupts = <0x19>;
			clocks = <0x03 0x5a 0x03 0x57 0x03 0x58>;
			cdns,fifo-width = <0x04>;
			#size-cells = <0x00>;
			cdns,trigger-address = <0x00>;
			compatible = "starfive,jh7110-qspi", "cdns,qspi-nor";
			status = "okay";
			reg = <0x00 0x13010000 0x00 0x10000 0x00 0x21000000 0x00 0x400000>;
			reset-names = "qspi", "qspi-ocp", "rstc_ref";
			cdns,fifo-depth = <0x100>;

			flash@0 {
				cdns,tshsl-ns = <0x01>;
				spi-max-frequency = <0xb71b00>;
				cdns,tsd2d-ns = <0x01>;
				cdns,read-delay = <0x05>;
				cdns,tslch-ns = <0x01>;
				compatible = "jedec,spi-nor";
				reg = <0x00>;
				cdns,tchsh-ns = <0x01>;

				partitions {
					#address-cells = <0x01>;
					#size-cells = <0x01>;
					compatible = "fixed-partitions";

					reserved-data@600000 {
						reg = <0x600000 0xa00000>;
					};

					uboot-env@f0000 {
						reg = <0xf0000 0x10000>;
					};

					spl@0 {
						reg = <0x00 0x80000>;
					};

					uboot@100000 {
						reg = <0x100000 0x400000>;
					};
				};
			};
		};

		clock-controller@13020000 {
			#reset-cells = <0x01>;
			clock-names = "osc", "gmac1_rmii_refin", "gmac1_rgmii_rxin", "i2stx_bclk_ext", "i2stx_lrck_ext", "i2srx_bclk_ext", "i2srx_lrck_ext", "tdm_ext", "mclk_ext", "pll0_out", "pll1_out", "pll2_out";
			clocks = <0x25 0x2d 0x2e 0x29 0x2a 0x1d 0x1e 0x18 0x1b 0x2f 0x00 0x2f 0x01 0x2f 0x02>;
			#clock-cells = <0x01>;
			compatible = "starfive,jh7110-syscrg";
			reg = <0x00 0x13020000 0x00 0x10000>;
			phandle = <0x03>;
		};

		cache-controller@2010000 {
			cache-size = <0x200000>;
			cache-level = <0x02>;
			cache-sets = <0x800>;
			interrupts = <0x01 0x03 0x04 0x02>;
			cache-unified;
			compatible = "starfive,jh7110-ccache", "sifive,ccache0", "cache";
			reg = <0x00 0x2010000 0x00 0x4000 0x00 0x8000000 0x00 0x2000000 0x00 0xa000000 0x00 0x2000000>;
			phandle = <0x01>;
			cache-block-size = <0x40>;
		};

		phy@10210000 {
			starfive,sys-syscon = <0x1c 0x18>;
			starfive,stg-syscon = <0x20 0x148 0x1f4>;
			#phy-cells = <0x00>;
			compatible = "starfive,jh7110-pcie-phy";
			reg = <0x00 0x10210000 0x00 0x10000>;
			phandle = <0x24>;
		};

		serial@10010000 {
			reg-io-width = <0x04>;
			clock-names = "baudclk", "apb_pclk";
			resets = <0x03 0x55 0x03 0x56>;
			interrupts = <0x21>;
			clocks = <0x03 0x94 0x03 0x93>;
			compatible = "snps,dw-apb-uart";
			status = "disabled";
			reg = <0x00 0x10010000 0x00 0x10000>;
			reg-shift = <0x02>;
		};

		pinctrl@17020000 {
			gpio-controller;
			resets = <0x36 0x02>;
			interrupts = <0x55>;
			compatible = "starfive,jh7110-aon-pinctrl";
			#interrupt-cells = <0x02>;
			reg = <0x00 0x17020000 0x00 0x10000>;
			#gpio-cells = <0x02>;
			interrupt-controller;
		};

		i2c@10040000 {
			#address-cells = <0x01>;
			clock-names = "ref";
			resets = <0x03 0x4d>;
			interrupts = <0x24>;
			clocks = <0x03 0x8b>;
			#size-cells = <0x00>;
			compatible = "snps,designware-i2c";
			status = "disabled";
			reg = <0x00 0x10040000 0x00 0x10000>;
		};

		clock-controller@10230000 {
			#reset-cells = <0x01>;
			clock-names = "osc", "hifi4_core", "stg_axiahb", "usb_125m", "cpu_bus", "hifi4_axi", "nocstg_bus", "apb_bus";
			clocks = <0x25 0x03 0x36 0x03 0x08 0x03 0x5f 0x03 0x02 0x03 0x37 0x03 0x06 0x03 0x0b>;
			#clock-cells = <0x01>;
			compatible = "starfive,jh7110-stgcrg";
			reg = <0x00 0x10230000 0x00 0x10000>;
			phandle = <0x22>;
		};

		mailbox@13060000 {
			clock-names = "clk_apb";
			resets = <0x03 0x44>;
			interrupts = <0x1a 0x1b>;
			clocks = <0x03 0x71>;
			#mbox-cells = <0x02>;
			compatible = "starfive,mail_box";
			status = "okay";
			reg = <0x00 0x13060000 0x00 0x1000>;
			phandle = <0x0b>;
			reset-names = "mbx_rre";
		};

		clock-controller@19810000 {
			power-domains = <0x30 0x05>;
			#reset-cells = <0x01>;
			clock-names = "isp_top_core", "isp_top_axi", "noc_bus_isp_axi", "dvp_clk";
			resets = <0x03 0x29 0x03 0x2a 0x03 0x1c>;
			clocks = <0x03 0x33 0x03 0x34 0x03 0x35 0x3e>;
			#clock-cells = <0x01>;
			compatible = "starfive,jh7110-ispcrg";
			reg = <0x00 0x19810000 0x00 0x10000>;
			phandle = <0x3c>;
		};

		i2c@12060000 {
			pinctrl-names = "default";
			#address-cells = <0x01>;
			i2c-sda-hold-time-ns = <0x12c>;
			pinctrl-0 = <0x27>;
			clock-names = "ref";
			i2c-scl-falling-time-ns = <0x1fe>;
			i2c-sda-falling-time-ns = <0x1fe>;
			resets = <0x03 0x52>;
			interrupts = <0x33>;
			clocks = <0x03 0x90>;
			#size-cells = <0x00>;
			clock-frequency = <0x186a0>;
			compatible = "snps,designware-i2c";
			status = "okay";
			reg = <0x00 0x12060000 0x00 0x10000>;

			cm32181@10 {
				compatible = "capella,cm32181";
				status = "okay";
				reg = <0x10>;
			};

			hid@2c {
				irq-gpio = <0x16 0x1e 0x00>;
				compatible = "hid-over-i2c";
				post-power-on-delay-ms = <0xc8>;
				status = "okay";
				reg = <0x2c>;
				hid-descr-addr = <0x20>;
			};

			cm32183@29 {
				compatible = "capella,cm32183";
				status = "okay";
				reg = <0x29>;
			};
		};

		ethernet@16040000 {
			snps,multicast-filter-bins = <0x40>;
			snps,txpbl = <0x10>;
			clock-names = "stmmaceth", "pclk", "ptp_ref", "tx", "gtx";
			snps,en-tx-lpi-clockgating;
			snps,fixed-burst;
			resets = <0x03 0x42 0x03 0x43>;
			interrupts = <0x4e 0x4d 0x4c>;
			clocks = <0x03 0x62 0x03 0x61 0x03 0x66 0x03 0x6a 0x03 0x6b>;
			snps,no-pbl-x8;
			snps,tso;
			starfive,syscon = <0x1c 0x90 0x02>;
			snps,rxpbl = <0x10>;
			compatible = "starfive,jh7110-dwmac", "snps,dwmac-5.20";
			status = "disabled";
			tx-fifo-depth = <0x800>;
			interrupt-names = "macirq", "eth_wake_irq", "eth_lpi";
			snps,force_thresh_dma_mode;
			rx-fifo-depth = <0x800>;
			reg = <0x00 0x16040000 0x00 0x10000>;
			reset-names = "stmmaceth", "ahb";
			snps,axi-config = <0x37>;
			snps,perfect-filter-entries = <0x100>;
		};

		spi@120a0000 {
			arm,primecell-periphid = <0x41022>;
			#address-cells = <0x01>;
			num-cs = <0x01>;
			clock-names = "sspclk", "apb_pclk";
			resets = <0x03 0x4b>;
			interrupts = <0x37>;
			clocks = <0x03 0x89 0x03 0x89>;
			#size-cells = <0x00>;
			compatible = "arm,pl022", "arm,primecell";
			status = "disabled";
			reg = <0x00 0x120a0000 0x00 0x10000>;
		};

		i2s@100e0000 {
			pinctrl-names = "default";
			pinctrl-0 = <0x1f>;
			clock-names = "i2sclk", "apb", "mclk", "mclk_inner", "mclk_ext", "bclk", "lrck", "bclk_ext", "lrck_ext";
			resets = <0x03 0x63 0x03 0x64>;
			clocks = <0x03 0xb0 0x03 0xaf 0x03 0x12 0x03 0x11 0x1b 0x03 0xb3 0x03 0xb5 0x1d 0x1e>;
			dma-names = "tx", "rx";
			#sound-dai-cells = <0x00>;
			starfive,syscon = <0x1c 0x18 0x02>;
			compatible = "starfive,jh7110-i2srx";
			status = "okay";
			reg = <0x00 0x100e0000 0x00 0x1000>;
			phandle = <0x51>;
			dmas = <0x00 0x19 0x18>;
		};

		watchdog@13070000 {
			clock-names = "apb", "core";
			resets = <0x03 0x6d 0x03 0x6e>;
			clocks = <0x03 0x7a 0x03 0x7b>;
			compatible = "starfive,jh7110-wdt";
			reg = <0x00 0x13070000 0x00 0x10000>;
		};

		gpu@18000000 {
			power-domains = <0x30 0x02>;
			clock-names = "clk_bv", "clk_apb", "clk_rtc", "clk_core", "clk_sys", "clk_axi";
			current-clock = <0x7a1200>;
			resets = <0x03 0x15 0x03 0x16>;
			interrupts = <0x52>;
			clocks = <0x03 0x2d 0x03 0x30 0x03 0x31 0x03 0x2e 0x03 0x2f 0x03 0x32>;
			compatible = "img-gpu";
			status = "okay";
			reg = <0x00 0x18000000 0x00 0x100000 0x00 0x130c000 0x00 0x10000>;
			reset-names = "rst_apb", "rst_doma";
		};

		i2s@120c0000 {
			pinctrl-names = "default";
			pinctrl-0 = <0x2b>;
			clock-names = "i2sclk", "apb", "mclk", "mclk_inner", "mclk_ext", "bclk", "lrck", "bclk_ext", "lrck_ext";
			resets = <0x03 0x67 0x03 0x68>;
			clocks = <0x03 0xa9 0x03 0xa8 0x03 0x12 0x03 0x11 0x1b 0x03 0xac 0x03 0xae 0x29 0x2a>;
			dma-names = "tx";
			#sound-dai-cells = <0x00>;
			compatible = "starfive,jh7110-i2stx1";
			status = "okay";
			reg = <0x00 0x120c0000 0x00 0x1000>;
			phandle = <0x50>;
			dmas = <0x19 0x30>;
		};

		usb@10100000 {
			starfive,sys-iomux = <0x21 0x80>;
			#address-cells = <0x01>;
			clock-names = "lpm", "stb", "apb", "axi", "utmi_apb", "phy";
			starfive,stg-syscon = <0x20 0x04>;
			resets = <0x22 0x0a 0x22 0x08 0x22 0x07 0x22 0x09 0x22 0x10>;
			clocks = <0x22 0x04 0x22 0x05 0x22 0x01 0x22 0x03 0x22 0x02 0x22 0x09>;
			#size-cells = <0x01>;
			compatible = "starfive,jh7110-usb";
			ranges = <0x00 0x00 0x10100000 0x100000>;
			status = "okay";
			dr_mode = "host";
			reset-names = "pwrup", "apb", "axi", "utmi_apb", "phy";

			usb@0 {
				phy-names = "cdns3,usb2-phy", "cdns3,usb3-phy";
				reg-names = "otg", "xhci", "dev";
				interrupts = <0x64 0x6c 0x6e>;
				compatible = "cdns,usb3";
				interrupt-names = "host", "peripheral", "otg";
				phys = <0x23 0x24>;
				reg = <0x00 0x10000 0x10000 0x10000 0x20000 0x10000>;
			};
		};
	};

	snd-card1 {
		simple-audio-card,name = "Starfive-HDMI-Sound-Card";
		#address-cells = <0x01>;
		#size-cells = <0x00>;
		compatible = "simple-audio-card";

		simple-audio-card,dai-link@0 {
			mclk-fs = <0x100>;
			format = "i2s";
			frame-master = <0x53>;
			status = "okay";
			bitclock-master = <0x53>;
			reg = <0x00>;

			cpu {
				phandle = <0x53>;
				sound-dai = <0x54>;
			};

			codec {
				sound-dai = <0x55>;
			};
		};
	};

	dvp-clock {
		clock-output-names = "dvp_clk";
		#clock-cells = <0x00>;
		clock-frequency = <0x46cf710>;
		compatible = "fixed-clock";
		phandle = <0x3e>;
	};

	i2srx-lrck-ext-clock {
		clock-output-names = "i2srx_lrck_ext";
		#clock-cells = <0x00>;
		clock-frequency = <0x2ee00>;
		compatible = "fixed-clock";
		phandle = <0x1e>;
	};

	gpio-restart {
		priority = <0xe0>;
		compatible = "gpio-restart";
		gpios = <0x16 0x23 0x00>;
	};

	rfkill_wifi {
		radio-type = "wlan";
		shutdown-gpios = <0x16 0x37 0x00>;
		label = "Wi-Fi";
		compatible = "rfkill-gpio";
	};

	gpio-keys {
		autorepeat;
		compatible = "gpio-keys";
		status = "okay";

		camera-en-sw {
			label = "camera en switch";
			linux,input-type = <0x05>;
			linux,code = <0x09>;
			debounce-interval = <0x0a>;
			gpios = <0x16 0x38 0x01>;
		};

		mic-mute-sw {
			label = "mic mute switch";
			linux,input-type = <0x05>;
			linux,code = <0x0e>;
			debounce-interval = <0x0a>;
			gpios = <0x16 0x3b 0x01>;
		};
	};

	tdm-ext-clock {
		clock-output-names = "tdm_ext";
		#clock-cells = <0x00>;
		clock-frequency = <0x2ee0000>;
		compatible = "fixed-clock";
		phandle = <0x18>;
	};

	mclk-ext-clock {
		clock-output-names = "mclk_ext";
		#clock-cells = <0x00>;
		clock-frequency = <0xbb8000>;
		compatible = "fixed-clock";
		phandle = <0x1b>;
	};

	tda988x_pin {
		compatible = "starfive,tda998x_rgb_pin";
		status = "disabled";
	};

	opp-table-0 {
		opp-shared;
		compatible = "operating-points-v2";
		phandle = <0x02>;

		opp-500000000 {
			opp-microvolt = "", "\f5";
			opp-hz = <0x00 0x1dcd6500>;
		};

		opp-1250000000 {
			opp-microvolt = <0xf4240>;
			opp-hz = <0x00 0x4a817c80>;
		};

		opp-625000000 {
			opp-microvolt = "", "\f5";
			opp-hz = <0x00 0x2540be40>;
			opp-suspend;
		};

		opp-750000000 {
			opp-microvolt = "", "\f5";
			opp-hz = <0x00 0x2cb41780>;
			opp-suspend;
		};

		opp-417000000 {
			opp-microvolt = "", "\f5";
			opp-hz = <0x00 0x18daea40>;
		};

		opp-1500000000 {
			opp-microvolt = <0xfde80>;
			opp-hz = <0x00 0x59682f00>;
		};

		opp-375000000 {
			opp-microvolt = "", "\f5";
			opp-hz = <0x00 0x165a0bc0>;
		};

		opp-312500000 {
			opp-microvolt = "", "\f5";
			opp-hz = <0x00 0x12a05f20>;
		};
	};

	mailbox_client {
		compatible = "starfive,mailbox-test";
		status = "okay";
		mboxes = <0x0b 0x00 0x01 0x0b 0x01 0x00>;
		mbox-names = "rx", "tx";
	};

	hdmitx0-pixel-clock {
		clock-output-names = "hdmitx0_pixelclk";
		#clock-cells = <0x00>;
		clock-frequency = <0x11b3dc40>;
		compatible = "fixed-clock";
		phandle = <0x41>;
	};

	aliases {
		i2c3 = "/soc/i2c@12030000";
		i2c1 = "/soc/i2c@10040000";
		mmc1 = "/soc/mmc@16020000";
		serial3 = "/soc/serial@12000000";
		i2c6 = "/soc/i2c@12060000";
		pcie0 = "/soc/pcie@940000000";
		i2c4 = "/soc/i2c@12040000";
		i2c2 = "/soc/i2c@10050000";
		i2c0 = "/soc/i2c@10030000";
		mmc0 = "/soc/mmc@16010000";
		pcie1 = "/soc/pcie@9c0000000";
		i2c5 = "/soc/i2c@12050000";
		serial0 = "/soc/serial@10000000";
	};

	i2stx-bclk-ext-clock {
		clock-output-names = "i2stx_bclk_ext";
		#clock-cells = <0x00>;
		clock-frequency = <0xbb8000>;
		compatible = "fixed-clock";
		phandle = <0x29>;
	};

	clk-ext-camera {
		#clock-cells = <0x00>;
		clock-frequency = <0x16e3600>;
		compatible = "fixed-clock";
	};

	gmac0-rmii-refin-clock {
		clock-output-names = "gmac0_rmii_refin";
		#clock-cells = <0x00>;
		compatible = "fixed-clock";
		phandle = <0x39>;
	};

	chosen {
		linux,uefi-mmap-size = <0x5f0>;
		bootargs = "BOOT_IMAGE=/boot/vmlinuz-6.6.20 root=LABEL=cloudimg-rootfs ro efi=debug earlycon sysctl.kernel.watchdog_thresh=60";
		boot-hartid = <0x01>;
		linux,uefi-mmap-start = <0x00 0xf0f74068>;
		linux,uefi-mmap-desc-size = <0x28>;
		linux,uefi-mmap-desc-ver = <0x01>;
		linux,uefi-system-table = <0x00 0xf7ed9d10>;
		stdout-path = "serial0:115200n8";
	};

	gmac0-rgmii-rxin-clock {
		clock-output-names = "gmac0_rgmii_rxin";
		#clock-cells = <0x00>;
		compatible = "fixed-clock";
		phandle = <0x3a>;
	};

	cpus {
		#address-cells = <0x01>;
		#size-cells = <0x00>;
		timebase-frequency = "", "=\t";

		cpu@1 {
			i-tlb-sets = <0x01>;
			clock-names = "cpu";
			cpu-supply = <0x04>;
			clocks = <0x03 0x01>;
			d-cache-block-size = <0x40>;
			device_type = "cpu";
			compatible = "sifive,u74-mc", "riscv";
			mmu-type = "riscv,sv39";
			d-cache-size = <0x8000>;
			next-level-cache = <0x01>;
			i-cache-size = <0x8000>;
			reg = <0x01>;
			phandle = <0x06>;
			d-cache-sets = <0x40>;
			i-cache-block-size = <0x40>;
			operating-points-v2 = <0x02>;
			i-cache-sets = <0x40>;
			d-tlb-size = <0x28>;
			riscv,isa = "rv64imafdc_zba_zbb";
			tlb-split;
			i-tlb-size = <0x28>;
			d-tlb-sets = <0x01>;
			#cooling-cells = <0x02>;

			interrupt-controller {
				compatible = "riscv,cpu-intc";
				#interrupt-cells = <0x01>;
				phandle = <0x10>;
				interrupt-controller;
			};
		};

		cpu@4 {
			i-tlb-sets = <0x01>;
			clock-names = "cpu";
			cpu-supply = <0x04>;
			clocks = <0x03 0x01>;
			d-cache-block-size = <0x40>;
			device_type = "cpu";
			compatible = "sifive,u74-mc", "riscv";
			mmu-type = "riscv,sv39";
			d-cache-size = <0x8000>;
			next-level-cache = <0x01>;
			i-cache-size = <0x8000>;
			reg = <0x04>;
			phandle = <0x09>;
			d-cache-sets = <0x40>;
			i-cache-block-size = <0x40>;
			operating-points-v2 = <0x02>;
			i-cache-sets = <0x40>;
			d-tlb-size = <0x28>;
			riscv,isa = "rv64imafdc_zba_zbb";
			tlb-split;
			i-tlb-size = <0x28>;
			d-tlb-sets = <0x01>;
			#cooling-cells = <0x02>;

			interrupt-controller {
				compatible = "riscv,cpu-intc";
				#interrupt-cells = <0x01>;
				phandle = <0x13>;
				interrupt-controller;
			};
		};

		cpu-map {

			cluster0 {

				core3 {
					cpu = <0x08>;
				};

				core1 {
					cpu = <0x06>;
				};

				core4 {
					cpu = <0x09>;
				};

				core2 {
					cpu = <0x07>;
				};

				core0 {
					cpu = <0x05>;
				};
			};
		};

		cpu@2 {
			i-tlb-sets = <0x01>;
			clock-names = "cpu";
			cpu-supply = <0x04>;
			clocks = <0x03 0x01>;
			d-cache-block-size = <0x40>;
			device_type = "cpu";
			compatible = "sifive,u74-mc", "riscv";
			mmu-type = "riscv,sv39";
			d-cache-size = <0x8000>;
			next-level-cache = <0x01>;
			i-cache-size = <0x8000>;
			reg = <0x02>;
			phandle = <0x07>;
			d-cache-sets = <0x40>;
			i-cache-block-size = <0x40>;
			operating-points-v2 = <0x02>;
			i-cache-sets = <0x40>;
			d-tlb-size = <0x28>;
			riscv,isa = "rv64imafdc_zba_zbb";
			tlb-split;
			i-tlb-size = <0x28>;
			d-tlb-sets = <0x01>;
			#cooling-cells = <0x02>;

			interrupt-controller {
				compatible = "riscv,cpu-intc";
				#interrupt-cells = <0x01>;
				phandle = <0x11>;
				interrupt-controller;
			};
		};

		cpu@0 {
			device_type = "cpu";
			compatible = "sifive,s7", "riscv";
			status = "disabled";
			next-level-cache = <0x01>;
			i-cache-size = <0x4000>;
			reg = <0x00>;
			phandle = <0x05>;
			i-cache-block-size = <0x40>;
			i-cache-sets = <0x40>;
			riscv,isa = "rv64imac_zba_zbb";

			interrupt-controller {
				compatible = "riscv,cpu-intc";
				#interrupt-cells = <0x01>;
				phandle = <0x0f>;
				interrupt-controller;
			};
		};

		cpu@3 {
			i-tlb-sets = <0x01>;
			clock-names = "cpu";
			cpu-supply = <0x04>;
			clocks = <0x03 0x01>;
			d-cache-block-size = <0x40>;
			device_type = "cpu";
			compatible = "sifive,u74-mc", "riscv";
			mmu-type = "riscv,sv39";
			d-cache-size = <0x8000>;
			next-level-cache = <0x01>;
			i-cache-size = <0x8000>;
			reg = <0x03>;
			phandle = <0x08>;
			d-cache-sets = <0x40>;
			i-cache-block-size = <0x40>;
			operating-points-v2 = <0x02>;
			i-cache-sets = <0x40>;
			d-tlb-size = <0x28>;
			riscv,isa = "rv64imafdc_zba_zbb";
			tlb-split;
			i-tlb-size = <0x28>;
			d-tlb-sets = <0x01>;
			#cooling-cells = <0x02>;

			interrupt-controller {
				compatible = "riscv,cpu-intc";
				#interrupt-cells = <0x01>;
				phandle = <0x12>;
				interrupt-controller;
			};
		};
	};

	reserved-memory {
		#address-cells = <0x02>;
		#size-cells = <0x02>;
		ranges;

		opensbi@40000000 {
			reg = <0x00 0x40000000 0x00 0x80000>;
			phandle = <0x56>;
			no-map;
		};

		linux,cma {
			linux,cma-default;
			alignment = <0x00 0x1000>;
			alloc-ranges = <0x00 0x70000000 0x00 0x20000000>;
			compatible = "shared-dma-pool";
			size = <0x00 0x20000000>;
			reusable;
		};

		e24@c0000000 {
			reg = <0x00 0x6ce00000 0x00 0x1600000>;
			phandle = <0x49>;
		};

		xrpbuffer@f0000000 {
			reg = <0x00 0x69c00000 0x00 0x1ffffff 0x00 0x6bc00000 0x00 0x1000 0x00 0x6bc01000 0x00 0xfff000 0x00 0x6cc00000 0x00 0x1000>;
		};
	};

	i2srx-bclk-ext-clock {
		clock-output-names = "i2srx_bclk_ext";
		#clock-cells = <0x00>;
		clock-frequency = <0xbb8000>;
		compatible = "fixed-clock";
		phandle = <0x1d>;
	};
};
